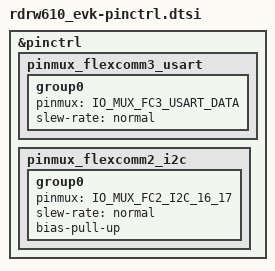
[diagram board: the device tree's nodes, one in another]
#include <nxp/rw/RW610-pinctrl.h>

&pinctrl {
	pinmux_flexcomm3_usart: pinmux_flexcomm3_usart {
		group0 {
			pinmux = <IO_MUX_FC3_USART_DATA>;
			slew-rate = "normal";
		};
	};

	pinmux_flexcomm2_i2c: pinmux_flexcomm2_i2c {
		group0 {
			pinmux = <IO_MUX_FC2_I2C_16_17>;
			slew-rate = "normal";
			bias-pull-up;
		};
	};
};
